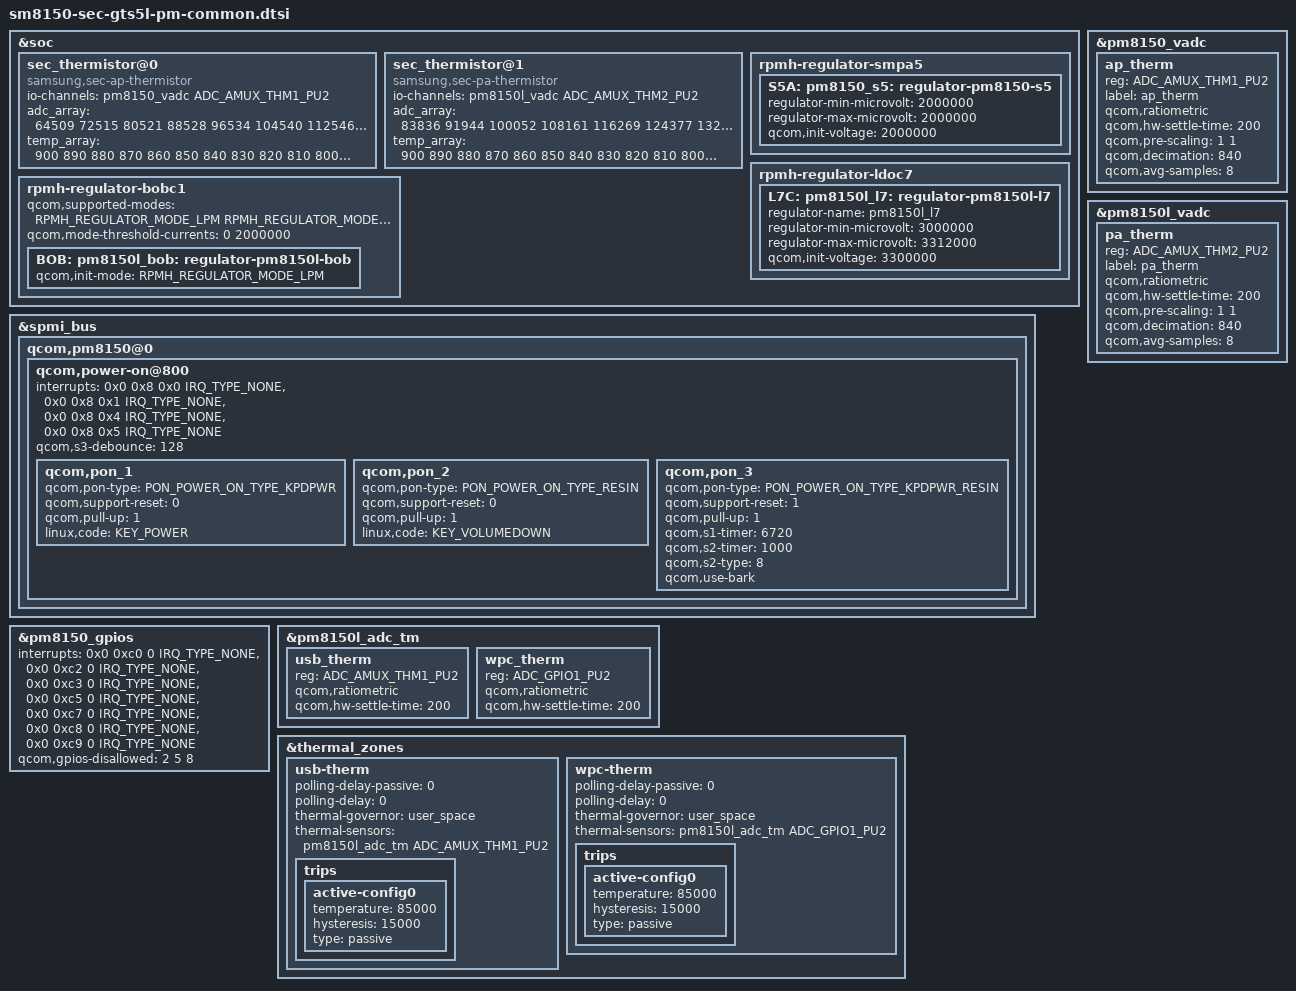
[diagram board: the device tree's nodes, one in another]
/* Copyright (c) 2014, The Linux Foundation. All rights reserved.
 *
 * This program is free software; you can redistribute it and/or modify
 * it under the terms of the GNU General Public License version 2 and
 * only version 2 as published by the Free Software Foundation.
 *
 * This program is distributed in the hope that it will be useful,
 * but WITHOUT ANY WARRANTY; without even the implied warranty of
 * MERCHANTABILITY or FITNESS FOR A PARTICULAR PURPOSE.  See the
 * GNU General Public License for more details.
 */

#include <dt-bindings/regulator/qcom,rpmh-regulator.h>

&soc {
	/* AP Thermistor table */
	sec_thermistor@0 {
		compatible = "samsung,sec-ap-thermistor";
		status = "okay";
		io-channels = <&pm8150_vadc ADC_AMUX_THM1_PU2>;
		io-channel-names = "ap_therm";
		adc_array = <64509 72515 80521 88528 96534 104540 112546 120552 128558 136564
				144570 152576 160582 168589 176595 184601 192607 200613 208620 216626
				224632 232638 240644 248650 256656 264662 272292 279922 287551 295181
				302811 312184 321557 330929 340302 349675 364156 378637 393118 407599
				422080 437002 451924 466847 481769 496691 512738 528784 544831 560877
				576924 592257 607590 622924 638257 653590 672984 692379 711773 731168
				750562 772552 794541 816531 838520 860510 885112 909714 934317 958919
				983521 1003867 1024213 1044558 1064904 1085250 1108260 1131271 1154281 1177292
				1200302 1223944 1247586 1271227 1294869 1318511 1335496 1352482 1369467 1386453
				1403438
				1419182 1434926 1450670 1466414 1482158 1498590 1515021 1531453 1547884 1564316
				1578663 1593010 1607356 1621703 1636050 1646007 1655964 1665920 1675877 1685834>;
		temp_array = <900 890 880 870 860 850 840 830 820 810
				800 790 780 770 760 750 740 730 720 710
				700 690 680 670 660 650 640 630 620 610
				600 590 580 570 560 550 540 530 520 510
				500 490 480 470 460 450 440 430 420 410
				400 390 380 370 360 350 340 330 320 310
				300 290 280 270 260 250 240 230 220 210
				200 190 180 170 160 150 140 130 120 110
				100 90 80 70 60 50 40 30 20 10
				0
				(-10) (-20) (-30) (-40) (-50) (-60) (-70) (-80) (-90) (-100)
				(-110)(-120)(-130)(-140)(-150)(-160)(-170)(-180)(-190) (-200)>;
	};

	/* PA Thermistor table */
	sec_thermistor@1 {
		compatible = "samsung,sec-pa-thermistor";
		status = "okay";
		io-channels = <&pm8150l_vadc ADC_AMUX_THM2_PU2>;
		io-channel-names = "pa_therm";
		adc_array = <83836 91944 100052 108161 116269 124377 132485 140593 148702 156810
				164918 173026 181134 189242 197350 205458 213566 221674 229783 237891
				245999 254107 262215 270324 278432 286540 294509 302478 310446 318415
				326384 337785 349187 360588 371990 383391 397163 410934 424706 438477
				452249 467361 482474 497586 512699 527811 545060 562309 579559 596808
				614057 632167 650277 668386 686496 704606 725034 745462 765891 786319
				806747 826924 847102 867279 887457 907634 930718 953802 976885 999969
				1023053 1045601 1068148 1090696 1113243 1135791 1157452 1179113 1200774 1222435
				1244096 1265047 1285999 1306950 1327902 1348853 1367460 1386068 1404675 1423283
				1441890
				1459040 1476189 1493339 1510488 1527638 1542205 1556773 1571340 1585908 1600475
				1613542 1626608 1639675 1652741 1665808 1675648 1685488 1695328 1705168 1715008>;
		temp_array = <900 890 880 870 860 850 840 830 820 810
				800 790 780 770 760 750 740 730 720 710
				700 690 680 670 660 650 640 630 620 610
				600 590 580 570 560 550 540 530 520 510
				500 490 480 470 460 450 440 430 420 410
				400 390 380 370 360 350 340 330 320 310
				300 290 280 270 260 250 240 230 220 210
				200 190 180 170 160 150 140 130 120 110
				100 90 80 70 60 50 40 30 20 10
				0
				(-10) (-20) (-30) (-40) (-50) (-60) (-70) (-80) (-90) (-100)
				(-110)(-120)(-130)(-140)(-150)(-160)(-170)(-180)(-190) (-200)>;
	};

	rpmh-regulator-smpa5 {
		S5A: pm8150_s5: regulator-pm8150-s5 {
			regulator-min-microvolt = <2000000>;
			regulator-max-microvolt = <2000000>;
			qcom,init-voltage = <2000000>;
		};
	};

	/* H/W request */
	rpmh-regulator-ldoc7 {
		L7C: pm8150l_l7: regulator-pm8150l-l7 {
			regulator-name = "pm8150l_l7";
			regulator-min-microvolt = <3000000>;
			regulator-max-microvolt = <3312000>;
			qcom,init-voltage = <3300000>;
		};
	};
	rpmh-regulator-bobc1 {
		qcom,supported-modes =
			<RPMH_REGULATOR_MODE_LPM
			 RPMH_REGULATOR_MODE_HPM>;
		qcom,mode-threshold-currents = <0 2000000>;

		BOB: pm8150l_bob: regulator-pm8150l-bob {
			qcom,init-mode = <RPMH_REGULATOR_MODE_LPM>;
		};
	};
};

&pm8150_vadc {
	/delete-node/ skin_therm;
	ap_therm {
		reg = <ADC_AMUX_THM1_PU2>;
		label = "ap_therm";
		qcom,ratiometric;
		qcom,hw-settle-time = <200>;
		qcom,pre-scaling = <1 1>;
		qcom,decimation = <840>;
		qcom,avg-samples = <8>;
	};
};

&pm8150l_vadc {
	/delete-node/ skin_msm_therm;
	pa_therm {
		reg = <ADC_AMUX_THM2_PU2>;
		label = "pa_therm";
		qcom,ratiometric;
		qcom,hw-settle-time = <200>;
		qcom,pre-scaling = <1 1>;
		qcom,decimation = <840>;
		qcom,avg-samples = <8>;
	};
};

&spmi_bus {
	qcom,pm8150@0 {
		qcom,power-on@800 {
			interrupts = <0x0 0x8 0x0 IRQ_TYPE_NONE>,
				     <0x0 0x8 0x1 IRQ_TYPE_NONE>,
					 <0x0 0x8 0x4 IRQ_TYPE_NONE>,
				     <0x0 0x8 0x5 IRQ_TYPE_NONE>;
			interrupt-names = "kpdpwr", "resin",
                    "resin-bark", "kpdpwr-resin-bark";

			qcom,s3-debounce = <128>;
			qcom,pon_1 {
				qcom,pon-type = <PON_POWER_ON_TYPE_KPDPWR>;
				qcom,support-reset = <0>;
				qcom,pull-up = <1>;
				linux,code = <KEY_POWER>;
			};

			qcom,pon_2 {
				qcom,pon-type = <PON_POWER_ON_TYPE_RESIN>;
				qcom,support-reset = <0>;
				qcom,pull-up = <1>;
				linux,code = <KEY_VOLUMEDOWN>;
			};

			qcom,pon_3 {
				qcom,pon-type = <PON_POWER_ON_TYPE_KPDPWR_RESIN>;
				qcom,support-reset = <1>;
				qcom,pull-up = <1>;
				qcom,s1-timer = <6720>;
				qcom,s2-timer = <1000>;
				qcom,s2-type = <8>;
				qcom,use-bark;
			};
		};
	};
};

&pm8150_gpios {
	interrupts = <0x0 0xc0 0 IRQ_TYPE_NONE>,
			<0x0 0xc2 0 IRQ_TYPE_NONE>,
			<0x0 0xc3 0 IRQ_TYPE_NONE>,
			<0x0 0xc5 0 IRQ_TYPE_NONE>,
			<0x0 0xc7 0 IRQ_TYPE_NONE>,
			<0x0 0xc8 0 IRQ_TYPE_NONE>,
			<0x0 0xc9 0 IRQ_TYPE_NONE>;
	interrupt-names = "pm8150_gpio1", "pm8150_gpio3",
			"pm8150_gpio4", "pm8150_gpio6", "pm8150_gpio7",
			"pm8150_gpio9", "pm8150_gpio10";
	qcom,gpios-disallowed = <2 5 8>;
};

&pm8150l_adc_tm {
	usb_therm {
		reg = <ADC_AMUX_THM1_PU2>;
		qcom,ratiometric;
		qcom,hw-settle-time = <200>;
	};

	wpc_therm {
		reg = <ADC_GPIO1_PU2>;
		qcom,ratiometric;
		qcom,hw-settle-time = <200>;
	};
};

&thermal_zones {
	 usb-therm {
		polling-delay-passive = <0>;
		polling-delay = <0>;
		thermal-governor = "user_space";
		thermal-sensors = <&pm8150l_adc_tm ADC_AMUX_THM1_PU2>;
		trips {
			active-config0 {
				temperature = <85000>;
				hysteresis = <15000>;
				type = "passive";
			};
		};
	};

	wpc-therm {
		polling-delay-passive = <0>;
		polling-delay = <0>;
		thermal-governor = "user_space";
		thermal-sensors = <&pm8150l_adc_tm ADC_GPIO1_PU2>;
		trips {
			active-config0 {
				temperature = <85000>;
				hysteresis = <15000>;
				type = "passive";
			};
		};
	};
};
